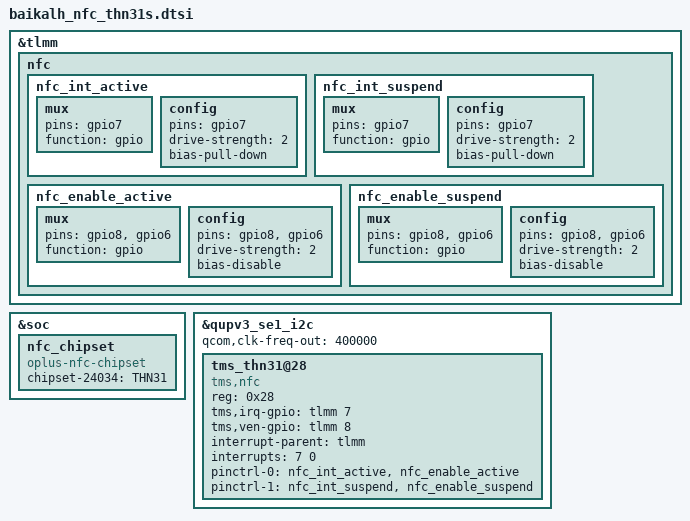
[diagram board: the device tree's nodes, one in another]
/**********************************************************************************
* Copyright (c)  2008-2020  Guangdong oplus Mobile Comm Corp., Ltd
* Description: oplus sn220e nfc dtsi
*
***********************************************************************************/
&tlmm {
  nfc {
         nfc_int_active: nfc_int_active {
                 /* active state */
                 mux {
                         /* GPIO 7: NFC Read Interrupt */
                         pins = "gpio7";
                         function = "gpio";
                     };

                 config {
                         pins = "gpio7";
                         drive-strength = <2>; /* 2 MA */
                         bias-pull-down;
                        };
         };

         nfc_int_suspend: nfc_int_suspend {
                 /* sleep state */
                 mux {
                         /* GPIO 7: NFC Read Interrupt */
                         pins = "gpio7";
                         function = "gpio";
                     };

                 config {
                         pins = "gpio7";
                         drive-strength = <2>; /* 2 MA */
                         bias-pull-down;
                        };
         };

         nfc_enable_active: nfc_enable_active {
                 mux {
                         /* 8: Enable,  6: CLOCK */
                         pins = "gpio8", "gpio6";
                         function = "gpio";
                     };

                 config {
                         pins = "gpio8", "gpio6";
                         drive-strength = <2>; /* 2 MA */
                         bias-disable;
                        };
         };

         nfc_enable_suspend: nfc_enable_suspend {
                 mux {
                         /* 8: Enable, 6: CLOCK */
                         pins = "gpio8", "gpio6";
                         function = "gpio";
                     };

                 config {
                         pins = "gpio8", "gpio6";
                         drive-strength = <2>; /* 2 MA */
                         bias-disable;
                        };
         };
    };
};

&soc {
    //add for nfc_chipset
    nfc_chipset {
        compatible = "oplus-nfc-chipset";
        chipset-24034 = "THN31";
    };
};

&qupv3_se1_i2c {
	status = "ok";
	qcom,clk-freq-out = <400000>;
	#address-cells = <1>;
	#size-cells = <0>;
	tms_thn31@28 {
		compatible = "tms,nfc";
		reg = <0x28>;
		tms,irq-gpio = <&tlmm 7 0x00>;
		tms,ven-gpio = <&tlmm 8 0x00>;
		interrupt-parent = <&tlmm>;
		interrupts = <7 0>;
		interrupt-names = "nfc_irq";
		pinctrl-names = "nfc_active", "nfc_suspend";
		pinctrl-0 = <&nfc_int_active &nfc_enable_active>;
		pinctrl-1 = <&nfc_int_suspend &nfc_enable_suspend>;
	};
};


